# ESP32-C61 register map
Vendor: ESPRESSIF SYSTEMS (SHANGHAI) CO., LTD.; Series: ESP32 C-Series; File version: 1
CPU: RV32IMAC r0p0, little endian, no MPU, no FPU, 0 interrupt priority bits
Address unit: 32 bits
Registers are 32-bit, read-write, reset 0x0 unless marked. A register's access mark holds for its fields unless they carry their own. Offsets are from the block's base; [hi:lo] are bit positions.

## HP_SYSTEM — HP_SYSTEM Peripheral
Base 0x60095000
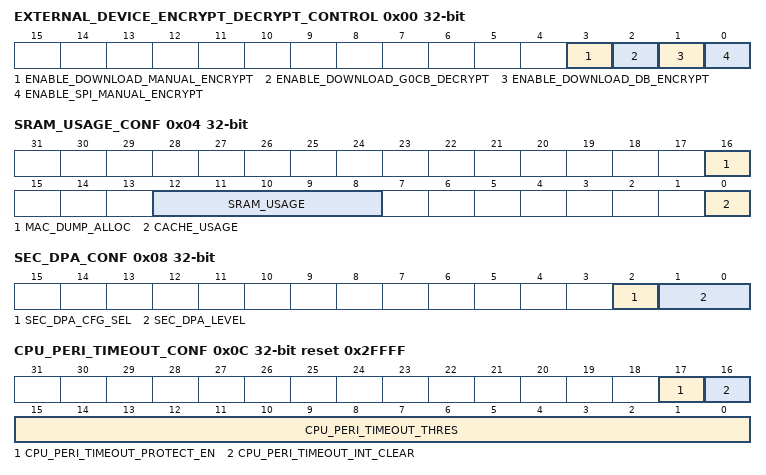
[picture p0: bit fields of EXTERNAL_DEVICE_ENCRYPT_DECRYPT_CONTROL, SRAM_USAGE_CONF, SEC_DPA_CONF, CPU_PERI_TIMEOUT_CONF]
0x00 EXTERNAL_DEVICE_ENCRYPT_DECRYPT_CONTROL — External device encryption/decryption configuration register
  [3] ENABLE_DOWNLOAD_MANUAL_ENCRYPT — Configures whether or not to enable MSPI XTS manual encryption in download boot mode. \\ 0: Disable\\ 1: Enable\\
  [2] ENABLE_DOWNLOAD_G0CB_DECRYPT — Configures whether or not to enable MSPI XTS auto decryption in download boot mode.\\ 0: Disable\\ 1: Enable\\
  [1] ENABLE_DOWNLOAD_DB_ENCRYPT — reserved
  [0] ENABLE_SPI_MANUAL_ENCRYPT — Configures whether or not to enable MSPI XTS manual encryption in SPI boot mode.\\ 0: Disable\\ 1: Enable\\
0x04 SRAM_USAGE_CONF access per field — HP memory usage configuration register
  [16] MAC_DUMP_ALLOC rw — Set this bit as 1 to add an offset (64KB) when mac-dump accessing hp-memory.
  [12:8] SRAM_USAGE rw — 0: cpu use hp-memory. 1:mac-dump accessing hp-memory.
  [0] CACHE_USAGE ro — reserved
0x08 SEC_DPA_CONF — HP anti-DPA security configuration register
  [2] SEC_DPA_CFG_SEL — Configures whether to select HP_SYSTEM_SEC_DPA_LEVEL or EFUSE_SEC_DPA_LEVEL (from eFuse) to control DPA level. \\ 0: Select EFUSE_SEC_DPA_LEVEL\\ 1: Select HP_SYSTEM_SEC_DPA_LEVEL\\
  [1:0] SEC_DPA_LEVEL — Configures whether or not to enable anti-DPA attack. Valid only when HP_SYSTEM_SEC_DPA_CFG_SEL is 0. \\ 0: Disable\\ 1-3: Enable. The larger the number, the higher the security level, which represents the ability to resist DPA attacks, with increased computational overhead of the hardware crypto-accelerators at the same time. \\
0x0C CPU_PERI_TIMEOUT_CONF access per field reset 0x2FFFF — CPU_PERI_TIMEOUT configuration register
  [17] CPU_PERI_TIMEOUT_PROTECT_EN rw — Configures whether or not to enable timeout protection for accessing CPU peripheral registers.\\ 0: Disable\\ 1: Enable\\
  [16] CPU_PERI_TIMEOUT_INT_CLEAR wo — Write 1 to clear timeout interrupt.
  [15:0] CPU_PERI_TIMEOUT_THRES rw — Configures the timeout threshold for bus access for accessing CPU peripheral register in the number of clock cycles of the clock domain.
0x10 CPU_PERI_TIMEOUT_ADDR ro
  [31:0] CPU_PERI_TIMEOUT_ADDR — Represents the address information of abnormal access.
0x14 CPU_PERI_TIMEOUT_UID ro
  [6:0] CPU_PERI_TIMEOUT_UID — Represents the master id[4:0] and master permission[6:5] when trigger timeout. This register will be cleared after the interrupt is cleared.
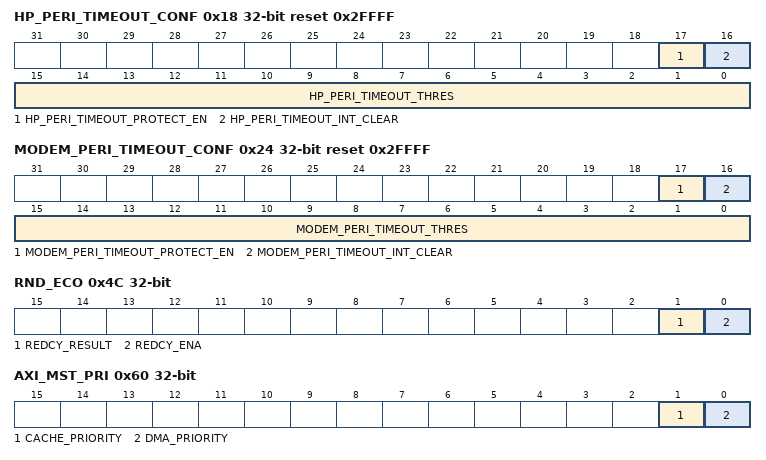
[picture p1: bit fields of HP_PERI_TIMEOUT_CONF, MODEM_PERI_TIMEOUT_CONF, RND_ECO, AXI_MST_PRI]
0x18 HP_PERI_TIMEOUT_CONF access per field reset 0x2FFFF — HP_PERI_TIMEOUT configuration register
  [17] HP_PERI_TIMEOUT_PROTECT_EN rw — Configures whether or not to enable timeout protection for accessing HP peripheral registers.\\ 0: Disable\\ 1: Enable\\
  [16] HP_PERI_TIMEOUT_INT_CLEAR wo — Configures whether or not to clear timeout interrupt.\\ 0: No effect\\ 1: Clear timeout interrupt\\
  [15:0] HP_PERI_TIMEOUT_THRES rw — Configures the timeout threshold for bus access for accessing HP peripheral register, corresponding to the number of clock cycles of the clock domain.
0x1C HP_PERI_TIMEOUT_ADDR ro
  [31:0] HP_PERI_TIMEOUT_ADDR — Represents the address information of abnormal access.
0x20 HP_PERI_TIMEOUT_UID ro
  [6:0] HP_PERI_TIMEOUT_UID — Represents the master id[4:0] and master permission[6:5] when trigger timeout. This register will be cleared after the interrupt is cleared.
0x24 MODEM_PERI_TIMEOUT_CONF access per field reset 0x2FFFF — MODEM_PERI_TIMEOUT configuration register
  [17] MODEM_PERI_TIMEOUT_PROTECT_EN rw — Set this bit as 1 to enable timeout protection for accessing modem registers
  [16] MODEM_PERI_TIMEOUT_INT_CLEAR wo — Set this bit as 1 to clear timeout interrupt
  [15:0] MODEM_PERI_TIMEOUT_THRES rw — Set the timeout threshold for bus access, corresponding to the number of clock cycles of the clock domain.
0x28 MODEM_PERI_TIMEOUT_ADDR ro
  [31:0] MODEM_PERI_TIMEOUT_ADDR — Record the address information of abnormal access
0x2C MODEM_PERI_TIMEOUT_UID ro
  [6:0] MODEM_PERI_TIMEOUT_UID — Record master id[4:0] & master permission[6:5] when trigger timeout. This register will be cleared after the interrupt is cleared.
0x30 ROM_TABLE_LOCK
  [0] ROM_TABLE_LOCK — Configures whether or not to lock the value contained in HP_SYSTEM_ROM_TABLE. \\ 0: Unlock \\ 1: Lock \\
0x34 ROM_TABLE
  [31:0] ROM_TABLE — Software ROM-Table register, whose content can be modified only when HP_SYSTEM_ROM_TABLE_LOCK is 0.
0x38 CORE_DEBUG_RUNSTALL_CONF ro — Core Debug RunStall configurion register
  [1] CORE_RUNSTALLED — Software can read this field to get the runstall status of hp-core. 1: stalled, 0: not stalled.
0x3C SPROM_CTRL reset 0x70 — reserved
  [31:0] SPROM_MEM_AUX_CTRL
0x40 SPRAM_CTRL reset 0x2070 — reserved
  [31:0] SPRAM_MEM_AUX_CTRL
0x44 SPRF_CTRL reset 0x2070 — reserved
  [31:0] SPRF_MEM_AUX_CTRL
0x48 SDPRF_CTRL — reserved
  [31:0] SDPRF_MEM_AUX_CTRL
0x4C RND_ECO access per field — redcy eco register.
  [1] REDCY_RESULT ro — Only reserved for ECO.
  [0] REDCY_ENA rw — Only reserved for ECO.
0x50 RND_ECO_LOW — redcy eco low register.
  [31:0] REDCY_LOW — Only reserved for ECO.
0x54 RND_ECO_HIGH reset 0xFFFFFFFF — redcy eco high register.
  [31:0] REDCY_HIGH — Only reserved for ECO.
0x58 DEBUG reset 0x1 — HP-SYSTEM debug register
  [0] FPGA_DEBUG — Reserved
0x5C CLOCK_GATE — HP-SYSTEM clock gating configure register
  [0] CLK_EN — Set this bit as 1 to force on clock gating.
0x60 AXI_MST_PRI — AXI mst priority configuration register
  [1] CACHE_PRIORITY — CACHE arbitration priority for command channels between masters connected to ext_mem_DW_axi
  [0] DMA_PRIORITY — AHB-DMA arbitration priority for command channels between masters connected to ext_mem_DW_axi
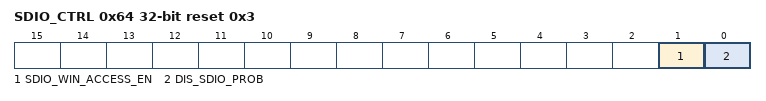
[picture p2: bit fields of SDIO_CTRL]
0x64 SDIO_CTRL reset 0x3 — SDIO Control configuration register
  [1] SDIO_WIN_ACCESS_EN — Enable sdio slave to access other peripherals on the chip
  [0] DIS_SDIO_PROB — Set this bit as 1 to disable SDIO_PROB function. disable by default.
0x3FC DATE reset 0x2412270 — Date control and version control register
  [27:0] DATE — Version control register.
